VERSION ""

NS_ :

BS_:

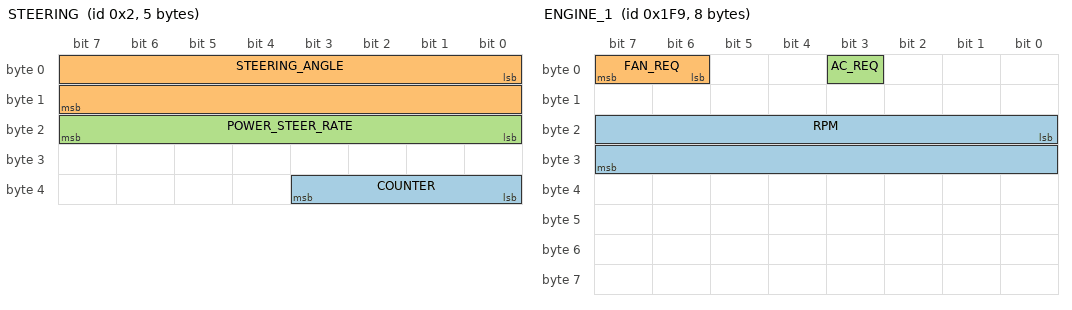
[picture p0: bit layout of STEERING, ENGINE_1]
BO_ 2 STEERING: 5 XXX
 SG_ COUNTER : 35|4@0+ (1,0) [0|255] "" XXX
 SG_ STEERING_ANGLE : 0|16@1- (0.1,0) [0|65535] "deg" XXX
 SG_ POWER_STEER_RATE : 23|8@0+ (1,0) [0|255] "" XXX

BO_ 505 ENGINE_1: 8 XXX
 SG_ RPM : 16|16@1+ (0.125,0) [0|45000] "R/min" XXX
 SG_ FAN_REQ : 6|2@1+ (1,0) [0|3] "" XXX
 SG_ AC_REQ : 3|1@1+ (1,0) [0|1] "" XXX

BO_ 561 ENGINE_2: 8 XXX
 SG_ Pedal_position : 16|8@1+ (0.5,0) [0|200] "%" XXX

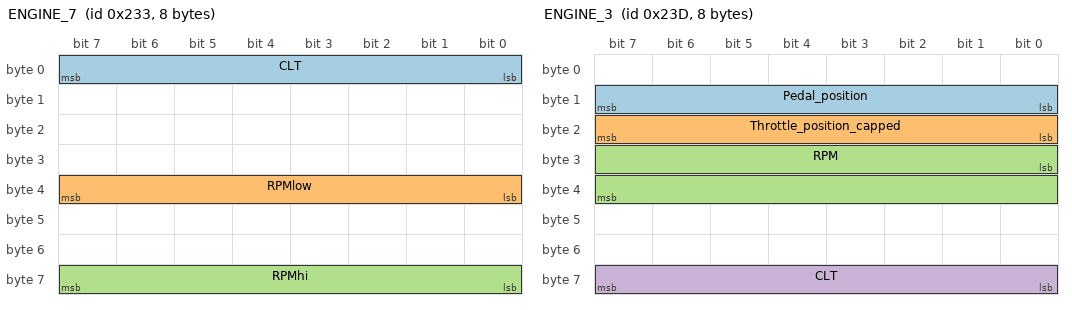
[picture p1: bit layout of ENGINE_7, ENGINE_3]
BO_ 563 ENGINE_7: 8 XXX
 SG_ CLT : 0|8@1+ (0.366666,0) [0|255] "C" XXX
 SG_ RPMlow : 32|8@1+ (3.15,0) [0|45000] "R/min" XXX
 SG_ RPMhi : 56|8@1+ (3.15,0) [0|45000] "R/min" XXX

BO_ 573 ENGINE_3: 8 XXX
 SG_ Pedal_position : 8|8@1+ (0.392,0) [0|255] "%" XXX
 SG_ Throttle_position_capped : 16|8@1+ (0.392,0) [0|255] "%" XXX
 SG_ RPM : 24|16@1+ (3.15,0) [0|45000] "R/min" XXX
 SG_ CLT : 56|8@1+ (0.366666,0) [0|255] "C" XXX

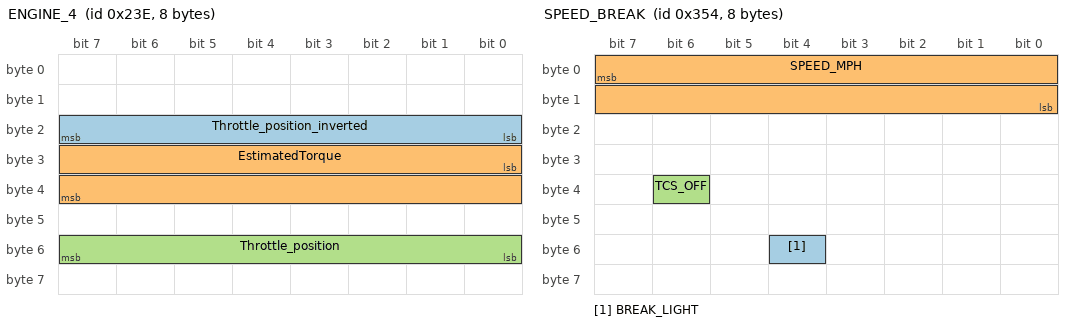
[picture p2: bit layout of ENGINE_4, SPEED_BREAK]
BO_ 574 ENGINE_4: 8 XXX
 SG_ Throttle_position_inverted : 16|8@1+ (0.392,0) [0|255] "%" XXX
 SG_ EstimatedTorque : 24|16@1+ (0.1,0) [0|45000] "nM" XXX
 SG_ Throttle_position : 48|8@1+ (0.392,0) [0|255] "%" XXX

BO_ 595 TCU_1: 8 XXX
 SG_ SHAFT_1_SPEED : 32|16@1+ (1,0) [0|45000] "r/min" XXX
 SG_ SHAFT_2_SPEED : 48|16@1+ (1,0) [0|45000] "r/min" XXX

BO_ 640 SPEED: 8 XXX
 SG_ SPEED : 32|16@1+ (0.01,0) [0|45000] "km/h" XXX

BO_ 644 ABS_1: 8 XXX
 SG_ WHEEL_1 : 0|16@1+ (0.01,0) [0|45000] "km/h" XXX
 SG_ WHEEL_2 : 15|16@1+ (0.01,0) [0|45000] "km/h" XXX

BO_ 645 ABS_2: 8 XXX
 SG_ WHEEL_3 : 0|16@1+ (0.01,0) [0|45000] "km/h" XXX
 SG_ WHEEL_4 : 15|16@1+ (0.01,0) [0|45000] "km/h" XXX

BO_ 852 SPEED_BREAK: 8 XXX
 SG_ BREAK_LIGHT : 52|1@0+ (1,0) [0|3] "" XXX
 SG_ SPEED_MPH : 7|16@0+ (0.0066,0) [0|65535] "mph" XXX
 SG_ TCS_OFF : 38|1@0+ (1,0) [0|255] "" XXX

BO_ 861 BCM: 8 XXX

BO_ 1361 ENGINE_5: 8 XXX
 SG_ CLT : 0|8@1+ (1,-45) [-45|150] "" XXX

BO_ 1408 ENGINE_6: 8 XXX
 SG_ RPM : 7|16@0+ (1.5,0) [0|65535] "" XXX
 SG_ OIL_TEMP : 32|8@1+ (1,-40) [-40|150] "" XXX

BU_: XXX CAMERA FRONT_RADAR ADRV APRK

VAL_ 262 DI_torqueDriver -4096 "SNA" ;
VAL_ 262 DI_torqueMotor -4096 "SNA" ;
VAL_ 262 DI_soptState 7 "SOPT_TEST_SNA" 4 "SOPT_TEST_NOT_RUN" 3 "SOPT_TEST_PASSED" 2 "SOPT_TEST_FAILED" 1 "SOPT_TEST_IN_PROGRESS" 0 "SOPT_PRE_TEST" ;
VAL_ 262 DI_motorRPM -32768 "SNA" ;
VAL_ 262 DI_pedalPos 255 "SNA" ;
VAL_ 278 DI_torqueEstimate -2048 "SNA" ;
VAL_ 278 DI_gear 7 "DI_GEAR_SNA" 4 "DI_GEAR_D" 3 "DI_GEAR_N" 2 "DI_GEAR_R" 1 "DI_GEAR_P" 0 "DI_GEAR_INVALID" ;
VAL_ 278 DI_brakePedal 1 "Applied" 0 "Not_applied" ;
VAL_ 278 DI_vehicleSpeed 4095 "SNA" ;
VAL_ 278 DI_gearRequest 7 "DI_GEAR_SNA" 4 "DI_GEAR_D" 3 "DI_GEAR_N" 2 "DI_GEAR_R" 1 "DI_GEAR_P" 0 "DI_GEAR_INVALID" ;
VAL_ 278 DI_torqueInterfaceFailure 1 "TORQUE_INTERFACE_FAILED" 0 "TORQUE_INTERFACE_NORMAL" ;
VAL_ 278 DI_brakePedalState 3 "SNA" 2 "INVALID" 1 "ON" 0 "OFF" ;
VAL_ 278 DI_epbParkRequest 1 "Park_requested" 0 "No_request" ;
VAL_ 278 DI_epbInterfaceReady 1 "EPB_INTERFACE_READY" 0 "EPB_INTERFACE_NOT_READY" ;
VAL_ 504 driverBrakeStatus 2 "APPLIED" 1 "NOT_APPLIED" ;
VAL_ 568 SpdCtrlLvr_Stat 32 "DN_1ST" 16 "UP_1ST" 8 "DN_2ND" 4 "UP_2ND" 2 "RWD" 1 "FWD" 0 "IDLE" ;
VAL_ 568 DTR_Dist_Rq 255 "SNA" 200 "ACC_DIST_7" 166 "ACC_DIST_6" 133 "ACC_DIST_5" 100 "ACC_DIST_4" 66 "ACC_DIST_3" 33 "ACC_DIST_2" 0 "ACC_DIST_1" ;
VAL_ 568 TurnIndLvr_Stat 3 "SNA" 2 "RIGHT" 1 "LEFT" 0 "IDLE" ;
VAL_ 568 HiBmLvr_Stat 3 "SNA" 2 "HIBM_FLSH_ON_PSD" 1 "HIBM_ON_PSD" 0 "IDLE" ;
VAL_ 568 WprWashSw_Psd 3 "SNA" 2 "WASH" 1 "TIPWIPE" 0 "NPSD" ;
VAL_ 568 WprWash_R_Sw_Posn_V2 3 "SNA" 2 "WASH" 1 "INTERVAL" 0 "OFF" ;
VAL_ 568 StW_Lvr_Stat 4 "STW_BACK" 3 "STW_FWD" 2 "STW_DOWN" 1 "STW_UP" 0 "NPSD" ;
VAL_ 568 StW_Cond_Psd 3 "SNA" 2 "DOWN" 1 "UP" 0 "NPSD" ;
VAL_ 568 HrnSw_Psd 3 "SNA" 2 "NDEF2" 1 "PSD" 0 "NPSD" ;
VAL_ 568 StW_Sw00_Psd 1 "PRESSED" 0 "NOT_PRESSED_SNA" ;
VAL_ 568 StW_Sw01_Psd 1 "PRESSED" 0 "NOT_PRESSED_SNA" ;
VAL_ 568 StW_Sw03_Psd 1 "PRESSED" 0 "NOT_PRESSED_SNA" ;
VAL_ 568 StW_Sw04_Psd 1 "PRESSED" 0 "NOT_PRESSED_SNA" ;
VAL_ 568 WprSw6Posn 7 "SNA" 6 "STAGE2" 5 "STAGE1" 4 "INTERVAL4" 3 "INTERVAL3" 2 "INTERVAL2" 1 "INTERVAL1" 0 "OFF" ;
VAL_ 598 DI_aebState 2 "ENABLED" 4 "FAULT" 7 "SNA" 1 "STANDBY" 3 "STANDSTILL" 0 "UNAVAILABLE" ;
VAL_ 598 DI_analogSpeed 4095 "SNA" ;
VAL_ 598 DI_cruiseState 2 "ENABLED" 5 "FAULT" 0 "OFF" 4 "OVERRIDE" 7 "PRE_CANCEL" 6 "PRE_FAULT" 1 "STANDBY" 3 "STANDSTILL" ;
VAL_ 598 DI_digitalSpeed 255 "SNA" ;
VAL_ 598 DI_immobilizerState 2 "AUTHENTICATING" 3 "DISARMED" 6 "FAULT" 4 "IDLE" 0 "INIT_SNA" 1 "REQUEST" 5 "RESET" ;
VAL_ 598 DI_speedUnits 1 "KPH" 0 "MPH" ;
VAL_ 598 DI_state 3 "ABORT" 4 "ENABLE" 2 "FAULT" 1 "STANDBY" 0 "UNAVAILABLE" ;
VAL_ 598 DI_systemState 3 "ABORT" 4 "ENABLE" 2 "FAULT" 1 "STANDBY" 0 "UNAVAILABLE" ;
VAL_ 598 DI_vehicleHoldState 2 "BLEND_IN" 4 "BLEND_OUT" 6 "FAULT" 7 "INIT" 5 "PARK" 1 "STANDBY" 3 "STANDSTILL" 0 "UNAVAILABLE" ;
VAL_ 703 DAS_setSpeed 4095 "SNA" ;
VAL_ 703 DAS_accState 15 "FAULT_SNA" 13 "ACC_CANCEL_GENERIC_SILENT" 11 "APC_SELFPARK_START" 10 "APC_UNPARK_COMPLETE" 9 "APC_PAUSE" 8 "APC_ABORT" 7 "APC_COMPLETE" 6 "APC_FORWARD" 5 "APC_BACKWARD" 4 "ACC_ON" 3 "ACC_HOLD" 0 "ACC_CANCEL_GENERIC" ;
VAL_ 703 DAS_aebEvent 3 "AEB_SNA" 2 "AEB_FAULT" 1 "AEB_ACTIVE" 0 "AEB_NOT_ACTIVE" ;
VAL_ 703 DAS_jerkMin 511 "SNA" ;
VAL_ 703 DAS_jerkMax 255 "SNA" ;
VAL_ 703 DAS_accelMin 511 "SNA" ;
